# COMPUTE_CLUSTER_J7AHP0_GIC500SS_0_GIC_DISTRIBUTOR register map
Vendor: Texas Instruments
Peripheral module from a debugger description file (folder J7_AHP).
Registers are 32-bit, access not given, no defined reset value unless marked. A register's access mark holds for its fields unless they carry their own. Offsets are as the file gives them; lines under a group give offsets from that group; [hi:lo] are bit positions; {n}, {i} and the like mark numbered series; 'fields as' and 'values as' point back to an identical list; <NAME> marks a mode.

## COMPUTE_CLUSTER_J7AHP0_GIC500SS_0_GIC_DISTRIBUTOR
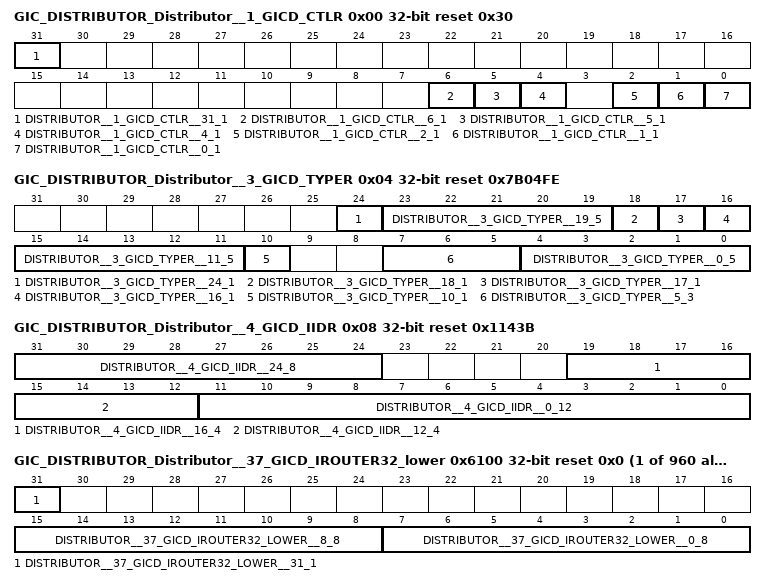
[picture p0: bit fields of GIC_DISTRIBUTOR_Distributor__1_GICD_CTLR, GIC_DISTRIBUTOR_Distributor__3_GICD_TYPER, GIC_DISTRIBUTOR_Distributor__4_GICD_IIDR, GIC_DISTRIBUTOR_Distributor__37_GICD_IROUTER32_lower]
0x00 GIC_DISTRIBUTOR_Distributor__1_GICD_CTLR rw reset 0x30
  [31] DISTRIBUTOR__1_GICD_CTLR__31_1, [6] DISTRIBUTOR__1_GICD_CTLR__6_1, [5] DISTRIBUTOR__1_GICD_CTLR__5_1, [4] DISTRIBUTOR__1_GICD_CTLR__4_1, [2] DISTRIBUTOR__1_GICD_CTLR__2_1, [1] DISTRIBUTOR__1_GICD_CTLR__1_1, [0] DISTRIBUTOR__1_GICD_CTLR__0_1
0x04 GIC_DISTRIBUTOR_Distributor__3_GICD_TYPER rw reset 0x7B04FE
  [24] DISTRIBUTOR__3_GICD_TYPER__24_1, [23:19] DISTRIBUTOR__3_GICD_TYPER__19_5, [18] DISTRIBUTOR__3_GICD_TYPER__18_1, [17] DISTRIBUTOR__3_GICD_TYPER__17_1, [16] DISTRIBUTOR__3_GICD_TYPER__16_1, [15:11] DISTRIBUTOR__3_GICD_TYPER__11_5, [10] DISTRIBUTOR__3_GICD_TYPER__10_1, [7:5] DISTRIBUTOR__3_GICD_TYPER__5_3, [4:0] DISTRIBUTOR__3_GICD_TYPER__0_5
0x08 GIC_DISTRIBUTOR_Distributor__4_GICD_IIDR rw reset 0x1143B
  [31:24] DISTRIBUTOR__4_GICD_IIDR__24_8, [19:16] DISTRIBUTOR__4_GICD_IIDR__16_4, [15:12] DISTRIBUTOR__4_GICD_IIDR__12_4, [11:0] DISTRIBUTOR__4_GICD_IIDR__0_12
0x40 GIC_DISTRIBUTOR_Distributor__5_GICD_SETSPI_NSR rw reset 0x0
  [9:0] DISTRIBUTOR__5_GICD_SETSPI_NSR__0_10
0x48 GIC_DISTRIBUTOR_Distributor__6_GICD_CLRSPI_NSR rw reset 0x0
  [9:0] DISTRIBUTOR__6_GICD_CLRSPI_NSR__0_10
0x50 GIC_DISTRIBUTOR_Distributor__7_GICD_SETSPI_SR rw reset 0x0
  [9:0] DISTRIBUTOR__7_GICD_SETSPI_SR__0_10
0x58 GIC_DISTRIBUTOR_Distributor__8_GICD_CLRSPI_SR rw reset 0x0
  [9:0] DISTRIBUTOR__8_GICD_CLRSPI_SR__0_10
0x80 GIC_DISTRIBUTOR_Distributor__9_GICD_IGROUPR0
{0x80+4i} GIC_DISTRIBUTOR_Distributor__10_GICD_IGROUPR{i} (i=1..30)
{0x100+4i} GIC_DISTRIBUTOR_Distributor__12_GICD_ISENABLER{i} (i=1..30)
{0x180+4i} GIC_DISTRIBUTOR_Distributor__14_GICD_ICENABLER{i} (i=1..30)
{0x200+4i} GIC_DISTRIBUTOR_Distributor__16_GICD_ISPENDR{i} (i=1..30)
{0x280+4i} GIC_DISTRIBUTOR_Distributor__18_GICD_ICPENDR{i} (i=1..30)
{0x300+4i} GIC_DISTRIBUTOR_Distributor__20_GICD_ISACTIVER{i} (i=1..30)
{0x380+4i} GIC_DISTRIBUTOR_Distributor__22_GICD_ICACTIVER{i} (i=1..30)
{0x400+4i} GIC_DISTRIBUTOR_Distributor__24_GICD_IPRIORITYR{i} (i=8..247)
{0x800+4i} GIC_DISTRIBUTOR_Distributor__26_GICD_ITARGETSR{i} (i=8..247)
{0xC00+4i} GIC_DISTRIBUTOR_Distributor__29_GICD_ICFGR{i} (i=2..61)
0xD00 GIC_DISTRIBUTOR_Distributor__30_GICD_IGRPMODR0
{0xD00+4i} GIC_DISTRIBUTOR_Distributor__31_GICD_IGRPMODR{i} (i=1..30)
0xE00 GIC_DISTRIBUTOR_Distributor__32_GICD_NSACR0
0xE04 GIC_DISTRIBUTOR_Distributor__32_GICD_NSACR1
{0xE00+4i} GIC_DISTRIBUTOR_Distributor__33_GICD_NSACR{i} (i=2..61)
{0x6000+8i} GIC_DISTRIBUTOR_Distributor__37_GICD_IROUTER{i}_lower rw reset 0x0 (i=32..991)
  [31] DISTRIBUTOR__37_GICD_IROUTER{i}_LOWER__31_1, [15:8] DISTRIBUTOR__37_GICD_IROUTER{i}_LOWER__8_8, [7:0] DISTRIBUTOR__37_GICD_IROUTER{i}_LOWER__0_8
{0x6004+8i} GIC_DISTRIBUTOR_Distributor__37_GICD_IROUTER{i}_upper (i=32..991)
0xC000 GIC_DISTRIBUTOR_Distributor__38_GICD_ESTATUSR rw reset 0x0
  [31] DISTRIBUTOR__38_GICD_ESTATUSR__31_1
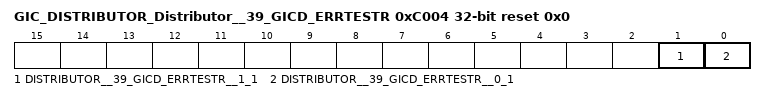
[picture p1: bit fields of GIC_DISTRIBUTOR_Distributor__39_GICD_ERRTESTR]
0xC004 GIC_DISTRIBUTOR_Distributor__39_GICD_ERRTESTR rw reset 0x0
  [1] DISTRIBUTOR__39_GICD_ERRTESTR__1_1, [0] DISTRIBUTOR__39_GICD_ERRTESTR__0_1
{0xC084+4i} GIC_DISTRIBUTOR_Distributor__40_GICD_SPISR{i} (i=0..29)
{0xFF2C+4i} GIC_DISTRIBUTOR_Distributor__{i}_GICD_PIDR{i-37} (i=41..44)
{0xFF2C+4i} GIC_DISTRIBUTOR_Distributor__{i}_GICD_PIDR{i-45} (i=45..48)
{0xFF2C+4i} GIC_DISTRIBUTOR_Distributor__{i}_GICD_CIDR{i-49} (i=49..52)
